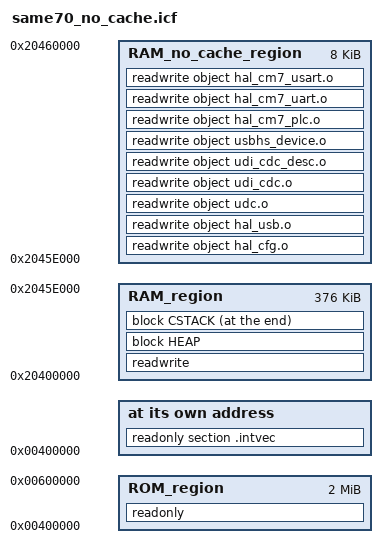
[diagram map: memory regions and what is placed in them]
/* Define symbol non_cache */
define symbol __NON_CACHE__ = 0x2000;

/*###ICF### Section handled by ICF editor, don't touch! ****/
/*-Editor annotation file-*/
/* IcfEditorFile="$TOOLKIT_DIR$\config\ide\IcfEditor\cortex_v1_0.xml" */
/*-Specials-*/
define symbol __ICFEDIT_intvec_start__     = 0x00400000;
/*-Memory Regions-*/
define symbol __ICFEDIT_region_RAM_start__ = 0x20400000;
define symbol __ICFEDIT_region_RAM_end__   = 0x20460000 - __NON_CACHE__;
define symbol __ICFEDIT_region_NO_CACHE_RAM_start__ = 0x20460000 - __NON_CACHE__;
define symbol __ICFEDIT_region_NO_CACHE_RAM_end__   = 0x20460000;
define symbol __ICFEDIT_region_ROM_start__ = 0x00400000;
define symbol __ICFEDIT_region_ROM_end__   = 0x00600000;
/*-Sizes-*/
if (!isdefinedsymbol(__ICFEDIT_size_cstack__)) {
  define symbol __ICFEDIT_size_cstack__      = 0x0400;
}
if (!isdefinedsymbol(__ICFEDIT_size_heap__)) {
  define symbol __ICFEDIT_size_heap__        = 0x0200;
}
/**** End of ICF editor section. ###ICF###*/

define memory mem with size = 4G;
define region RAM_region    = mem:[from __ICFEDIT_region_RAM_start__ to __ICFEDIT_region_RAM_end__];
define region RAM_no_cache_region      = mem:[from __ICFEDIT_region_NO_CACHE_RAM_start__ to __ICFEDIT_region_NO_CACHE_RAM_end__];
define region ROM_region    = mem:[from __ICFEDIT_region_ROM_start__ to __ICFEDIT_region_ROM_end__];

define block CSTACK with alignment = 8, size = __ICFEDIT_size_cstack__ { };
define block HEAP   with alignment = 8, size = __ICFEDIT_size_heap__   { };

initialize by copy { readwrite };
do not initialize  { section .noinit };

place at address mem:__ICFEDIT_intvec_start__ { readonly section .intvec };
place in ROM_region                           { readonly };
place in RAM_no_cache_region                  { readwrite object hal_cfg.o,
												readwrite object hal_usb.o,
												readwrite object udc.o,
												readwrite object udi_cdc.o,
												readwrite object udi_cdc_desc.o,
												readwrite object usbhs_device.o,
												readwrite object hal_cm7_plc.o,
												readwrite object hal_cm7_uart.o,
                                                readwrite object hal_cm7_usart.o};

place in RAM_region                           { readwrite, block HEAP };
place at end of RAM_region                    { block CSTACK };
